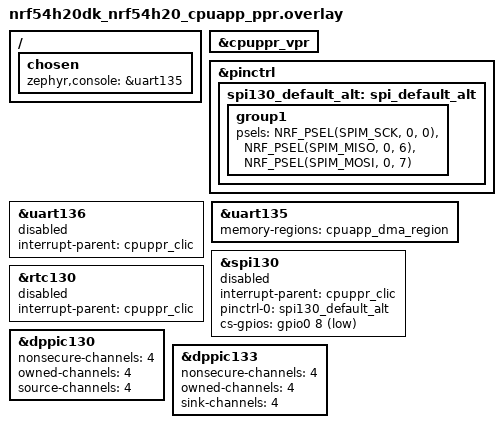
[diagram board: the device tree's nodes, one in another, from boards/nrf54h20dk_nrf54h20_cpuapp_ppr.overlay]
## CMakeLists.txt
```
#
# Copyright (c) 2026 Nordic Semiconductor
#
# SPDX-License-Identifier: LicenseRef-Nordic-5-Clause
#

cmake_minimum_required(VERSION 3.20.0)

find_package(Zephyr REQUIRED HINTS $ENV{ZEPHYR_BASE})
project(ppi_seq_spi)

FILE(GLOB app_sources src/*.c)

target_sources(app PRIVATE ${app_sources})
```

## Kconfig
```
#
# Copyright (c) 2026 Nordic Semiconductor ASA
#
# SPDX-License-Identifier: LicenseRef-Nordic-5-Clause
#

source "Kconfig.zephyr"

config PPI_SEQ_ON_PPR
	bool "Run on PPR"
```

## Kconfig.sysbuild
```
#
# Copyright (c) 2026 Nordic Semiconductor ASA
#
# SPDX-License-Identifier: LicenseRef-Nordic-5-Clause
#

if SOC_NRF54H20_CPUAPP

choice NETCORE
	default NETCORE_EMPTY
endchoice

endif # SOC_NRF54H20_CPUAPP

if SUPPORT_PPRCORE

choice PPRCORE

config PPRCORE_REMOTE
	bool "Remote"
	help
	  Include remote image as the PPR core image to use.

endchoice

if !PPRCORE_NONE

config PPRCORE_IMAGE_NAME
	default "remote" if PPRCORE_REMOTE

config PPRCORE_IMAGE_PATH
	default "$(APP_DIR)/remote" if PPRCORE_REMOTE

endif # !PPRCORE_NONE

endif # SUPPORT_PPRCORE

source "share/sysbuild/Kconfig"
```

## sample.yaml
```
sample:
  description: Sample showing PPI sequencer with SPI
  name: SPI PPI sequencer sample

common:
  tags:
    - ci_samples_peripheral_ppi

tests:
  sample.peripheral.ppi_seq_spi:
    harness: console
    harness_config:
      type: multi_line
      ordered: true
      regex:
        - "PPI Sequencer for SPI transfers .+"
        - "PPI sequence completed. Period: 1000, data received:\\d+, callback:\\d+, load:0.\\d%"
    integration_platforms:
      - nrf54h20dk/nrf54h20/cpuapp
      - nrf54l15dk/nrf54l15/cpuapp
      - nrf7120dk/nrf7120/cpuapp
    platform_allow:
      - nrf54h20dk/nrf54h20/cpuapp
      - nrf54l15dk/nrf54l15/cpuapp
      - nrf54lc10dk/nrf54lc10a/cpuapp
      - nrf54lm20dk/nrf54lm20a/cpuapp
      - nrf54lm20dk/nrf54lm20b/cpuapp
      - nrf54ls05dk/nrf54ls05a/cpuapp
      - nrf54ls05dk/nrf54ls05b/cpuapp
      - nrf54lv10dk/nrf54lv10a/cpuapp
      - nrf7120dk/nrf7120/cpuapp
      - nrf9251dk/nrf9251/cpuapp
  sample.peripheral.ppi_seq_spi.ppr:
    harness: console
    harness_config:
      type: multi_line
      ordered: true
      regex:
        - "PPI Sequencer for SPI transfers .+"
        - "PPI sequence completed. Period: 1000, data received:\\d+, callback:\\d+, load:0.\\d%"
    integration_platforms:
      - nrf54h20dk/nrf54h20/cpuapp
    platform_allow:
      - nrf54h20dk/nrf54h20/cpuapp
      - nrf9251dk/nrf9251/cpuapp
    extra_args:
      - SB_CONFIG_PPRCORE_REMOTE=y
      - ppi_seq_spi_CONFIG_NRFX_GPPI=y
      - ppi_seq_spi_FILE_SUFFIX=ppr
```

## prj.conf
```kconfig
CONFIG_PPI_SEQ=y
CONFIG_CPU_LOAD=y

# Low power with UART
CONFIG_UART_ASYNC_API=y
CONFIG_PINCTRL_KEEP_SLEEP_STATE=y

CONFIG_OUTPUT_DISASSEMBLY=y
```

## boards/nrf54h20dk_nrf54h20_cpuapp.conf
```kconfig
CONFIG_PM=y
CONFIG_SOC_NRF54H20_CPURAD_ENABLE=y
```

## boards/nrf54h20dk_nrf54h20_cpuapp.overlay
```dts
/*
 * Copyright (c) 2026 Nordic Semiconductor ASA
 *
 * SPDX-License-Identifier: LicenseRef-Nordic-5-Clause
 */

&pinctrl {
	spi130_default_alt: spi130_default_alt {
		group1 {
			psels = <NRF_PSEL(SPIM_SCK, 0, 0)>,
				<NRF_PSEL(SPIM_MISO, 0, 6)>,
				<NRF_PSEL(SPIM_MOSI, 0, 7)>;
		};
	};

	spi130_sleep_alt: spi130_sleep_alt {
		group1 {
			psels = <NRF_PSEL(SPIM_SCK, 0, 0)>,
				<NRF_PSEL(SPIM_MISO, 0, 6)>,
				<NRF_PSEL(SPIM_MOSI, 0, 7)>;
		};

		low-power-enable;
	};
};

&rtc130 {
	status = "reserved";
};

sample_spi: &spi130 {
	compatible = "nordic,ppi-seq-spi";
	status = "okay";
	pinctrl-0 = <&spi130_default_alt>;
	pinctrl-1 = <&spi130_sleep_alt>;
	pinctrl-names = "default", "sleep";
	overrun-character = <0x00>;
	memory-regions = <&cpuapp_dma_region>;
	cs-gpios = <&gpio0 8 GPIO_ACTIVE_LOW>;
	frequency = <8000000>;
	rtc = <&rtc130>;
};
```

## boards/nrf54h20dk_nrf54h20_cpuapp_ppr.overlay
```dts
/*
 * Copyright (c) 2026 Nordic Semiconductor ASA
 *
 * SPDX-License-Identifier: LicenseRef-Nordic-5-Clause
 */

/ {
	chosen {
		zephyr,console = &uart135;
	};
};

&cpuppr_vpr {
	status = "okay";
};

&pinctrl {
	spi130_default_alt: spi_default_alt {
		group1 {
			psels = <NRF_PSEL(SPIM_SCK, 0, 0)>,
				<NRF_PSEL(SPIM_MISO, 0, 6)>,
				<NRF_PSEL(SPIM_MOSI, 0, 7)>;
		};
	};
};

/* Console uart for PPR for testing reason it's the UART typically used by the cpuapp. */
&uart136 {
	status = "reserved";
	interrupt-parent = <&cpuppr_clic>;
};

&uart135 {
	status = "okay";
	memory-regions = <&cpuapp_dma_region>;
};

sample_spi: &spi130 {
	status = "reserved";
	interrupt-parent = <&cpuppr_clic>;
	pinctrl-0 = <&spi130_default_alt>;
	pinctrl-names = "default";
	cs-gpios = <&gpio0 8 GPIO_ACTIVE_LOW>;
};

sample_rtc: &rtc130 {
	status = "reserved";
	interrupt-parent = <&cpuppr_clic>;
};

&dppic130 {
	status = "okay";
	nonsecure-channels = <4>;
	owned-channels = <4>;
	/* RTC130->SPI130 */
	source-channels = <4>;
};

&dppic133 {
	status = "okay";

	nonsecure-channels = <4>;
	owned-channels = <4>;
	/* SPI130<-RTC130/GRTC */
	sink-channels = <4>;
};
```

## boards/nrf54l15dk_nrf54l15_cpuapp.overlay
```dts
/*
 * Copyright (c) 2026 Nordic Semiconductor ASA
 *
 * SPDX-License-Identifier: LicenseRef-Nordic-5-Clause
 */

&pinctrl {
	spi00_default_alt: spi00_default_alt {
		group1 {
			psels = <NRF_PSEL(SPIM_SCK, 2, 6)>,
				<NRF_PSEL(SPIM_MISO, 2, 9)>,
				<NRF_PSEL(SPIM_MOSI, 2, 8)>;
		};
	};

	spi00_sleep_alt: spi00_sleep_alt {
		group1 {
			psels = <NRF_PSEL(SPIM_SCK, 2, 6)>,
				<NRF_PSEL(SPIM_MISO, 2, 9)>,
				<NRF_PSEL(SPIM_MOSI, 2, 8)>;
			low-power-enable;
		};
	};
};

/delete-node/ &mx25r64;

sample_spi: &spi00 {
	compatible = "nordic,ppi-seq-spi";
	status = "okay";
	pinctrl-0 = <&spi00_default_alt>;
	pinctrl-1 = <&spi00_sleep_alt>;
	pinctrl-names = "default", "sleep";
	overrun-character = <0x00>;
	cs-gpios = <&gpio2 10 GPIO_ACTIVE_LOW>;
	frequency = <8000000>;
};
```

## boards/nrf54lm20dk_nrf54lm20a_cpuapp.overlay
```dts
/*
 * Copyright (c) 2026 Nordic Semiconductor ASA
 *
 * SPDX-License-Identifier: LicenseRef-Nordic-5-Clause
 */

&pinctrl {
	spi00_default_alt: spi00_default_alt {
		group1 {
			psels = <NRF_PSEL(SPIM_SCK, 2, 1)>,
				<NRF_PSEL(SPIM_MISO, 2, 4)>,
				<NRF_PSEL(SPIM_MOSI, 2, 2)>;
		};
	};

	spi00_sleep_alt: spi00_sleep_alt {
		group1 {
			psels = <NRF_PSEL(SPIM_SCK, 2, 1)>,
				<NRF_PSEL(SPIM_MISO, 2, 4)>,
				<NRF_PSEL(SPIM_MOSI, 2, 2)>;
			low-power-enable;
		};
	};
};

/delete-node/ &mx25r64;

sample_spi: &spi00 {
	compatible = "nordic,ppi-seq-spi";
	status = "okay";
	pinctrl-0 = <&spi00_default_alt>;
	pinctrl-1 = <&spi00_sleep_alt>;
	pinctrl-names = "default", "sleep";
	overrun-character = <0x00>;
	cs-gpios = <&gpio2 10 GPIO_ACTIVE_LOW>;
	frequency = <DT_FREQ_M(8)>;
};
```

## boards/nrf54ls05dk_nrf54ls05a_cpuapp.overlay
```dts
/*
 * Copyright (c) 2026 Nordic Semiconductor ASA
 *
 * SPDX-License-Identifier: LicenseRef-Nordic-5-Clause
 */

&pinctrl {
	spi21_default_alt: spi21_default_alt {
		group1 {
			psels = <NRF_PSEL(SPIM_SCK, 1, 4)>,
				<NRF_PSEL(SPIM_MISO, 1, 5)>,
				<NRF_PSEL(SPIM_MOSI, 1, 6)>;
		};
	};

	spi21_sleep_alt: spi21_sleep_alt {
		group1 {
			psels = <NRF_PSEL(SPIM_SCK, 1, 4)>,
				<NRF_PSEL(SPIM_MISO, 1, 5)>,
				<NRF_PSEL(SPIM_MOSI, 1, 6)>;
			low-power-enable;
		};
	};
};

sample_spi: &spi21 {
	compatible = "nordic,ppi-seq-spi";
	status = "okay";
	pinctrl-0 = <&spi21_default_alt>;
	pinctrl-1 = <&spi21_sleep_alt>;
	pinctrl-names = "default", "sleep";
	overrun-character = <0x00>;
	cs-gpios = <&gpio1 8 GPIO_ACTIVE_LOW>;
	frequency = <DT_FREQ_M(8)>;
};
```

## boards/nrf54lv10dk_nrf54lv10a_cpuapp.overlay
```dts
/*
 * Copyright (c) 2026 Nordic Semiconductor ASA
 *
 * SPDX-License-Identifier: LicenseRef-Nordic-5-Clause
 */

&pinctrl {
	spi20_default_alt: spi20_default_alt {
		group1 {
			psels = <NRF_PSEL(SPIM_SCK, 1, 11)>,
				<NRF_PSEL(SPIM_MISO, 1, 8)>,
				<NRF_PSEL(SPIM_MOSI, 1, 9)>;
		};
	};

	spi20_sleep_alt: spi20_sleep_alt {
		group1 {
			psels = <NRF_PSEL(SPIM_SCK, 1, 11)>,
				<NRF_PSEL(SPIM_MISO, 1, 8)>,
				<NRF_PSEL(SPIM_MOSI, 1, 9)>;
			low-power-enable;
		};
	};
};

sample_spi: &spi20 {
	compatible = "nordic,ppi-seq-spi";
	status = "okay";
	pinctrl-0 = <&spi20_default_alt>;
	pinctrl-1 = <&spi20_sleep_alt>;
	pinctrl-names = "default", "sleep";
	overrun-character = <0x00>;
	cs-gpios = <&gpio1 0 GPIO_ACTIVE_LOW>;
	frequency = <DT_FREQ_M(8)>;
};
```

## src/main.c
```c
/*
 * Copyright (c) 2026 Nordic Semiconductor ASA
 *
 * SPDX-License-Identifier: LicenseRef-Nordic-5-Clause
 */

#include <string.h>
#include <stdlib.h>
#include <dmm.h>
#include <hal/nrf_gpio.h>
#include <hal/nrf_grtc.h>
#if DT_NODE_EXISTS(DT_NODELABEL(sample_rtc))
#include <hal/nrf_rtc.h>
#endif
#include <drivers/ppi_seq/ppi_seq_i2c_spi.h>
#include <zephyr/kernel.h>
#include <zephyr/sys/cpu_load.h>
#include <zephyr/drivers/pinctrl.h>
#include <zephyr/logging/log.h>
LOG_MODULE_REGISTER(app);

#ifdef CONFIG_SOC_NRF54H20_CPUPPR
#include <hal/nrf_vpr_csr.h>
#endif

#define SPIM_NODE DT_NODELABEL(sample_spi)
#define RTC_NODE DT_NODELABEL(sample_rtc)
#define TRANSFER_LENGTH 8
#define BATCH_LENGTH	16

static uint8_t tx_dma_buffer[TRANSFER_LENGTH] DMM_MEMORY_SECTION(SPIM_NODE);
static uint8_t rx_dma_buffer[2][BATCH_LENGTH * TRANSFER_LENGTH] DMM_MEMORY_SECTION(SPIM_NODE);
#ifdef CONFIG_HAS_NORDIC_DMM
static uint8_t rx_buffer[BATCH_LENGTH * TRANSFER_LENGTH];
#endif

struct sample_data {
	struct k_sem sem;
	uint32_t cb_cnt;
	uint32_t data_cnt;
};

static void ppi_seq_cb(const struct device *dev, struct ppi_seq_i2c_spi_batch *batch, bool last,
		       void *user_data)
{
	struct sample_data *data = user_data;

#ifdef CONFIG_HAS_NORDIC_DMM
	uint32_t *src = (uint32_t *)batch->desc.spim.p_rx_buffer;
	uint32_t *dst = (uint32_t *)rx_buffer;

	/* Perform copying from DMA memory to the user buffer. Data is not used, it's done only
	 * to estimate CPU load and power consumption.
	 */
	for (int i = 0; i < (TRANSFER_LENGTH * batch->batch_cnt) / sizeof(uint32_t); i++) {
		dst[i] = src[i];
	}
#endif

	data->data_cnt += (batch->desc.spim.rx_length * batch->batch_cnt);
	data->cb_cnt++;

	if (last) {
		k_sem_give(&data->sem);
	}
}

static int seq_run(const struct device *dev, uint32_t timeout_ms, uint32_t period, bool log_load)
{
	struct sample_data data;
	uint32_t repeat = (timeout_ms * USEC_PER_MSEC) / (BATCH_LENGTH * period);
	struct ppi_seq_i2c_spi_job job = {
		.desc = {
			.spim = {
				.p_tx_buffer = tx_dma_buffer,
				.tx_length = TRANSFER_LENGTH,
				.p_rx_buffer = rx_dma_buffer[0],
				.rx_length = TRANSFER_LENGTH,
			}
		},
		.rx_second_buf = rx_dma_buffer[1],
		.repeat = repeat,
		.batch_cnt = BATCH_LENGTH,
		.tx_postinc = false,
		.cb = ppi_seq_cb,
		.user_data = &data
	};
	int rv;
	int load = 0;

	memset(&data, 0, sizeof(data));
	k_sem_init(&data.sem, 0, 1);

	if (IS_ENABLED(CONFIG_CPU_LOAD)) {
		load = cpu_load_get(true);
	}

	rv = ppi_seq_i2c_spi_start(dev, period, &job);
	if (rv < 0) {
		LOG_ERR("PPI sequencer start failed %d", rv);
		return rv;
	}

	rv = k_sem_take(&data.sem, K_MSEC(timeout_ms + 10));
	if (rv < 0) {
		LOG_ERR("PPI sequencer timeout: %d", rv);
		return rv;
	}

	if (IS_ENABLED(CONFIG_CPU_LOAD)) {
		load = cpu_load_get(true);
	}

	printk("PPI sequence completed. Period: %d, data received:%d, callback:%d, load:%d.%d%%\n",
	       period, data.data_cnt, data.cb_cnt, load / 10, load % 10);

	return 0;
}

static int manual_xfer(const struct device *dev)
{
	union ppi_seq_i2c_spi_xfer_desc desc;

	desc.spim.p_tx_buffer = tx_dma_buffer;
	desc.spim.tx_length = 2;
	desc.spim.p_rx_buffer = rx_dma_buffer[0];
	desc.spim.rx_length = 2;

	tx_dma_buffer[0] = 0xA4;
	tx_dma_buffer[1] = 0xB5;
	tx_dma_buffer[1] = 0xC6;
	return ppi_seq_i2c_spi_xfer(dev, &desc);
}

/* Function sets up a PPI connection that is used by the sequencer running on cpuppr. It is
 * done to reduce code size on cpuppr by not requiring GPPI driver to be used there.
 */
static int setup_ppr_ppi_seq(void)
{
#if DT_NODE_EXISTS(DT_NODELABEL(sample_rtc))
	NRF_RTC_Type *rtc_reg = (NRF_RTC_Type *)DT_REG_ADDR(RTC_NODE);
	uint32_t tep = nrf_spim_task_address_get((NRF_SPIM_Type *)DT_REG_ADDR(SPIM_NODE),
				NRF_SPIM_TASK_START);
	uint32_t eep = nrf_rtc_event_address_get(rtc_reg, nrf_rtc_compare_event_get(1));
	nrfx_gppi_handle_t handle;
	int rv;

	rv = nrfx_gppi_conn_alloc(eep, tep, &handle);
	if (rv < 0) {
		return rv;
	}

	nrfx_gppi_conn_enable(handle);
#endif

	return 0;
}

int main(void)
{
	static const struct device *ppi_seq_spi_dev =
		COND_CODE_1(CONFIG_NORDIC_VPR_LAUNCHER, (NULL), (DEVICE_DT_GET(SPIM_NODE)));
	int rv;
	bool log_cpu_load = true;
	uint32_t periods[] = {
			      1000,
			      2500,
			      5000,
			      10000,
			      25000,
			      50000
#ifdef USE_RTC
			      ,
			      100000
#endif
	};
	uint32_t idx = 0;
	uint32_t timeout;

	if (IS_ENABLED(CONFIG_NORDIC_VPR_LAUNCHER)) {
		/* Setup DPPI connections for the sequencer on cpuapp if sequencer is running
		 * on cpuppr core. With this approach PPR does not require to have GPPI driver.
		 */
		printk("PPI Sequencer for SPI transfers on PPR %s\n", CONFIG_BOARD_TARGET);
		return setup_ppr_ppi_seq();
	}

	if (!device_is_ready(ppi_seq_spi_dev)) {
		printk("PPI Sequencer with SPI is not ready\n");
		return -EINVAL;
	}

	printk("PPI Sequencer for SPI transfers %s\n", CONFIG_BOARD_TARGET);


	while (1) {
		/* Execute standard blocking SPI transfer using the SPIM instance that is used
		 * by the sequencer.
		 */
		rv = manual_xfer(ppi_seq_spi_dev);
		if (rv < 0) {
			printk("Manual transfer failed:%d\n", rv);
			return rv;
		}

		/* Pick a timeout and execute batch operations. */
		timeout = periods[idx] <= 25000 ? 1000 : 3000;
		rv = seq_run(ppi_seq_spi_dev, timeout, periods[idx], log_cpu_load);
		if (rv < 0) {
			printk("Sequence failed:%d\n", rv);
			return rv;
		}

		idx++;
		if (idx == ARRAY_SIZE(periods)) {
			idx = 0;
		}
	}

	return 0;
}

#ifdef CONFIG_SOC_NRF54H20_CPUPPR
static int vpr_init(void)
{
	csr_write(VPRCSR_NORDIC_VPRNORDICSLEEPCTRL,
		  VPRCSR_NORDIC_VPRNORDICSLEEPCTRL_SLEEPSTATE_DEEPSLEEP);
	return 0;
}
SYS_INIT(vpr_init, PRE_KERNEL_1, 0);
#endif
```
